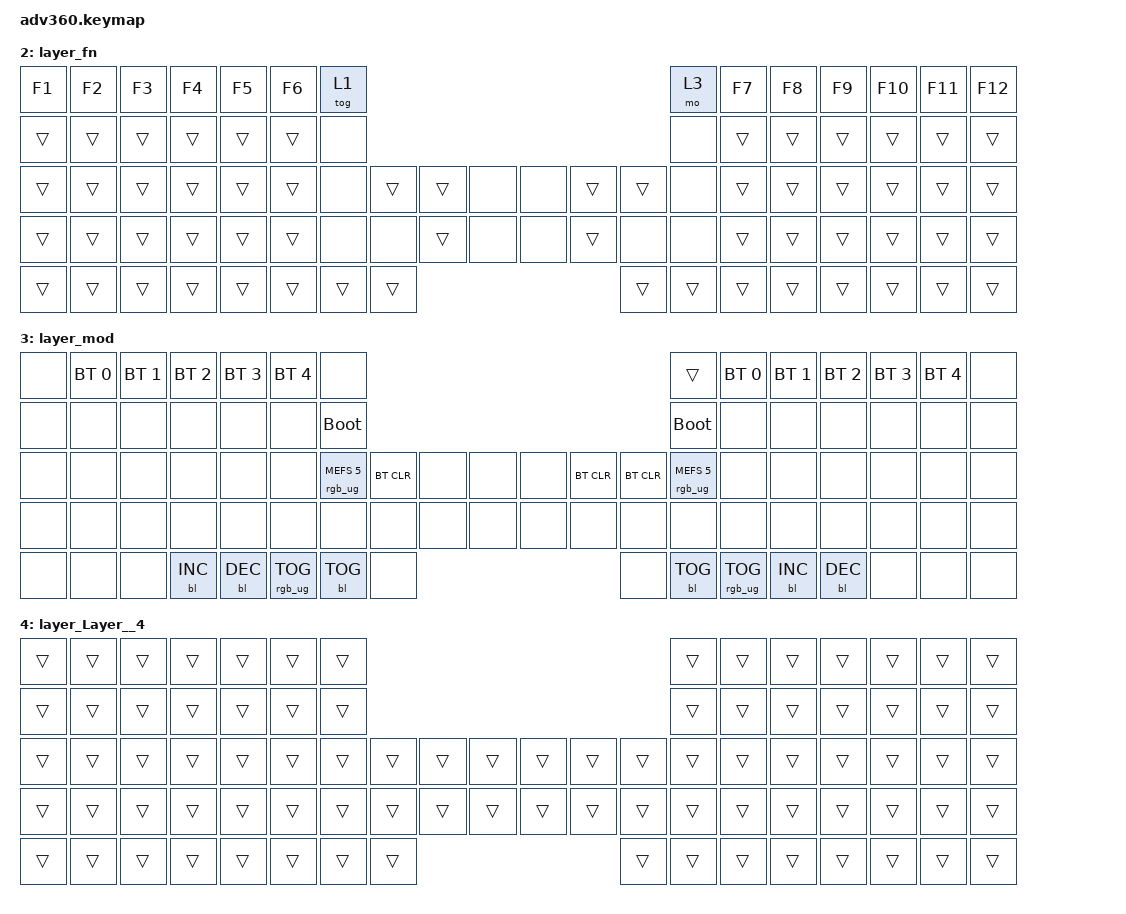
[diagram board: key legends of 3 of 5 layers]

/*
 * Copyright (c) 2020 The ZMK Contributors
 *
 * SPDX-License-Identifier: MIT
 */


/* THIS FILE WAS GENERATED!
 *
 * This file was generated automatically. You may or may not want to
 * edit it directly.
 */

#include <behaviors.dtsi>
#include <dt-bindings/zmk/keys.h>
#include <dt-bindings/zmk/bt.h>
#include <dt-bindings/zmk/rgb.h>
#include <dt-bindings/zmk/backlight.h>

/ {
  behaviors {
    #include "macros.dtsi"

    hm: homerow_mods {
        compatible = "zmk,behavior-hold-tap";
        label = "HOMEROW_MODS";
        #binding-cells = <2>;
        tapping-term-ms = <200>;
        quick_tap_ms = <175>;
        flavor = "tap-preferred";
        bindings = <&kp>, <&kp>;
    };
  };

    keymap {
        compatible = "zmk,keymap";


    default_layer {
      bindings = <
        &kp EQUAL &kp N1        &kp N2            &kp N3            &kp N4  &kp N5    &kp ESC                                                                                      &mo 3  &kp N6  &kp N7             &kp N8    &kp N9    &kp N0  &kp MINUS
        &kp TAB   &kp Q         &kp W             &kp E             &kp R   &kp T     &mo 1                                                                                      &mo 3   &kp Y   &kp U              &kp I     &kp O     &kp P   &kp BSLH
        &mo 1     &kp A         &kp S             &kp D             &kp F   &kp G     &kp LEFT_COMMAND       &kp LEFT_ALT  &kp LEFT_COMMAND   &kp LEFT_ARROW  &kp RIGHT_ARROW    &none   &kp H   &kp J              &kp K     &kp L  &kp SEMI    &kp SQT
        &kp LSHFT &kp Z         &kp X             &kp C             &kp V   &kp B                                  &kp HOME   &none   &none    &kp UP_ARROW            &none    &none   &kp N   &kp M          &kp COMMA   &kp DOT  &kp FSLH  &kp RSHFT
        &mo 3     &kp GRAVE     &kp LEFT_ALT      &kp LEFT_CONTROL  &kp LEFT_COMMAND  &kp SPACE  &kp BACKSPACE           &kp END                  &kp DOWN_ARROW        &kp ENTER  &kp DEL           &none  &kp RIGHT_CONTROL  &kp LBKT  &kp RBKT      &mo 1
      >;
    };

        layer_keypad {
            bindings = <
 &kp ESCAPE           &kp F1       &kp F2                &kp F3                 &kp F4     &kp F5                   &trans                                                                 &mo 3  &kp F6     &kp F7     &kp F8      &kp F9       &kp F10    &kp F11
    &kp TAB  &kp EXCLAMATION  &kp AT_SIGN        &kp LEFT_BRACE        &kp RIGHT_BRACE   &kp PIPE                    &none                                                                 &none   &kp Y  &kp KP_N7  &kp KP_N8   &kp KP_N9  &kp KP_MINUS    &kp F12
    &kp ESC        &kp POUND   &kp DOLLAR  &kp LEFT_PARENTHESIS  &kp RIGHT_PARENTHESIS  &kp GRAVE            &kp LEFT_META  &kp LCTRL  &kp LALT   &kp LGUI  &kp RCTRL      &none   &kp H  &kp KP_N4  &kp KP_N5   &kp KP_N6   &kp KP_PLUS    &kp SQT
  &kp LSHFT      &kp PERCENT    &kp CARET      &kp LEFT_BRACKET      &kp RIGHT_BRACKET  &kp TILDE                     &kp HOME   &kp PG_UP                                          &kp N  &kp KP_N1  &kp KP_N2   &kp KP_N3  &kp KP_ENTER  &kp RSHFT
      &mo 2        &kp GRAVE     &kp CAPS              &kp LEFT              &kp RIGHT                            &kp BSPC    &kp DEL   &kp END                  &kp PG_DN  &kp ENTER  &kp KP_N0             &kp UP   &kp DOWN  &kp KP_DOT      &kp RBKT      &mo 2
            >;
        };

        layer_fn {
            bindings = <
 &kp F1  &kp F2  &kp F3  &kp F4  &kp F5  &kp F6            &tog 1                                                   &mo 3  &kp F7  &kp F8  &kp F9  &kp F10  &kp F11  &kp F12
 &trans  &trans  &trans  &trans  &trans  &trans             &none                                                   &none  &trans  &trans  &trans   &trans   &trans   &trans
 &trans  &trans  &trans  &trans  &trans  &trans             &none  &trans  &trans   &none   &none  &trans  &trans   &none  &trans  &trans  &trans   &trans   &trans   &trans
 &trans  &trans  &trans  &trans  &trans  &trans             &none   &none  &trans   &none   &none  &trans   &none   &none  &trans  &trans  &trans   &trans   &trans   &trans
 &trans  &trans  &trans  &trans  &trans                    &trans  &trans  &trans                  &trans  &trans  &trans          &trans  &trans   &trans   &trans   &trans
            >;
        };

        layer_mod {
            bindings = <
  &none  &bt BT_SEL 0  &bt BT_SEL 1  &bt BT_SEL 2  &bt BT_SEL 3  &bt BT_SEL 4                             &none                                                                              &trans  &bt BT_SEL 0  &bt BT_SEL 1  &bt BT_SEL 2  &bt BT_SEL 3  &bt BT_SEL 4   &none
  &none         &none         &none         &none         &none         &none                       &bootloader                                                                         &bootloader         &none         &none         &none         &none         &none   &none
  &none         &none         &none         &none         &none         &none            &rgb_ug RGB_MEFS_CMD 5  &bt BT_CLR   &none   &none   &none  &bt BT_CLR  &bt BT_CLR  &rgb_ug RGB_MEFS_CMD 5         &none         &none         &none         &none         &none   &none
  &none         &none         &none         &none         &none         &none                             &none       &none   &none   &none   &none       &none       &none                   &none         &none         &none         &none         &none         &none   &none
  &none         &none         &none    &bl BL_INC    &bl BL_DEC                                 &rgb_ug RGB_TOG  &bl BL_TOG   &none                       &none  &bl BL_TOG         &rgb_ug RGB_TOG                  &bl BL_INC    &bl BL_DEC         &none         &none   &none
            >;
        };

        layer_Layer__4 {
            bindings = <
 &trans  &trans  &trans  &trans  &trans  &trans            &trans                                                  &trans  &trans  &trans  &trans  &trans  &trans  &trans
 &trans  &trans  &trans  &trans  &trans  &trans            &trans                                                  &trans  &trans  &trans  &trans  &trans  &trans  &trans
 &trans  &trans  &trans  &trans  &trans  &trans            &trans  &trans  &trans  &trans  &trans  &trans  &trans  &trans  &trans  &trans  &trans  &trans  &trans  &trans
 &trans  &trans  &trans  &trans  &trans  &trans            &trans  &trans  &trans  &trans  &trans  &trans  &trans  &trans  &trans  &trans  &trans  &trans  &trans  &trans
 &trans  &trans  &trans  &trans  &trans                    &trans  &trans  &trans                  &trans  &trans  &trans          &trans  &trans  &trans  &trans  &trans
            >;
        };

    };
};
